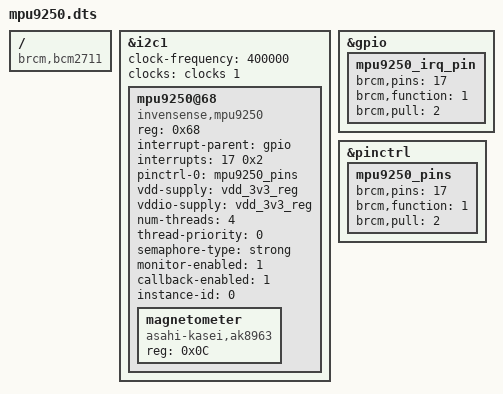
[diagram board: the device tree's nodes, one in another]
/dts-v1/;
/plugin/;

/ {
    compatible = "brcm,bcm2711";

    // Enable and configure I2C1 bus
    fragment@0 {
        target = <&i2c1>;
        __overlay__ {
            #address-cells = <1>;
            #size-cells = <0>;
            status = "okay";
            clock-frequency = <400000>;
            clocks = <&clocks 1>;

            mpu9250@68 {
                compatible = "invensense,mpu9250";
                reg = <0x68>;
                interrupt-parent = <&gpio>;
                interrupts = <17 0x2>;
                pinctrl-names = "default";
                pinctrl-0 = <&mpu9250_pins>;
                vdd-supply = <&vdd_3v3_reg>;
                vddio-supply = <&vdd_3v3_reg>;
                status = "okay";
                num-threads = <4>;
                thread-priority = <0>;
                semaphore-type = "strong";
                monitor-enabled = <1>;
                callback-enabled = <1>;
                instance-id = <0>;

                magnetometer {
                    compatible = "asahi-kasei,ak8963";
                    reg = <0x0C>;
                    status = "okay";
                };
            };
        };
    };

    // Configure GPIO for interrupt
    fragment@1 {
        target = <&gpio>;
        __overlay__ {
            mpu9250_irq_pin: mpu9250_irq_pin {
                brcm,pins = <17>;
                brcm,function = <1>;
                brcm,pull = <2>;
            };
        };
    };

    // Pin control configuration
    fragment@2 {
        target = <&pinctrl>;
        __overlay__ {
            mpu9250_pins: mpu9250_pins {
                brcm,pins = <17>;
                brcm,function = <1>;
                brcm,pull = <2>;
            };
        };
    };

    // Dynamic configuration overrides
    __overrides__ {
        addr = <&mpu9250>,"reg:0";
        irq_pin = <&mpu9250_irq_pin>,"brcm,pins:0";
        i2c_bus = <&i2c1>,"status";
        i2c_speed = <&i2c1>,"clock-frequency:0";
        accel_scale = <&mpu9250>,"accel-scale:0";
        gyro_scale = <&mpu9250>,"gyro-scale:0";
        sample_rate = <&mpu9250>,"sample-rate:0";
        instance_id = <&mpu9250>,"instance-id:0";
        num_threads = <&mpu9250>,"num-threads:0";
        thread_priority = <&mpu9250>,"thread-priority:0";
        semaphore_type = <&mpu9250>,"semaphore-type";
        monitor_enabled = <&mpu9250>,"monitor-enabled:0";
        callback_enabled = <&mpu9250>,"callback-enabled:0";
    };
};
